# STM32WL5X_CM4 register map
File version: 2.2
CPU: CM4 r0p1, little endian, MPU, no FPU, 4 interrupt priority bits
Registers are 32-bit, read-write, reset 0x0 unless marked. A register's access mark holds for its fields unless they carry their own. Offsets are from the block's base; [hi:lo] are bit positions; {n}, {i} and the like mark numbered series; 'fields as' and 'values as' point back to an identical list.

## GPIOH — General-purpose I/Os
Base 0x48001C00
0x00 MODER reset 0xC0 — GPIO port mode register
  [7:6] MODER3 — Port x configuration bits (y = 0..15)
    0=Input mode (reset state); 1=Output (General purpose output mode); 2=Alternate function mode; 3=Analog mode
0x04 OTYPER — GPIO port output type register
  [3] OT3 — Port x configuration bits (y = 0..15)
    0=PushPull (Output push-pull (reset state)); 1=OpenDrain (Output open-drain)
0x08 OSPEEDR — GPIO port output speed register
  [7:6] OSPEEDR3 — Port x configuration bits (y = 0..15)
    0=LowSpeed; 1=MediumSpeed; 2=HighSpeed; 3=VeryHighSpeed
0x0C PUPDR — GPIO port pull-up/pull-down register
  [7:6] PUPDR3 — Port x configuration bits (y = 0..15)
    0=Floating (No pull-up, pull-down); 1=PullUp; 2=PullDown
0x10 IDR ro — GPIO port input data register
  [3] IDR3 — Port input data (y = 0..15)
    0=Low (Input is logic low); 1=High (Input is logic high)
0x14 ODR — GPIO port output data register
  [3] ODR3 — Port output data (y = 0..15)
    0=Low (Set output to logic low); 1=High (Set output to logic high)
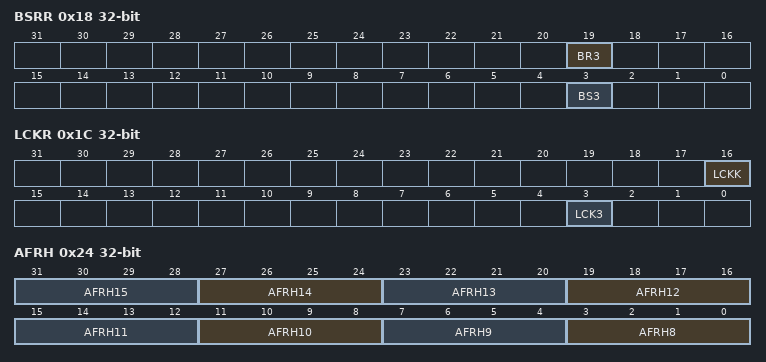
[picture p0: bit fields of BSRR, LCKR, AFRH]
0x18 BSRR wo — GPIO port bit set/reset register
  [19] BR3 — Port x reset bit y (y = 0..15)
    1=Resets the corresponding ODRx bit
  [3] BS3 — Port x set bit y (y= 0..15)
    1=Set (Sets the corresponding ODRx bit)
0x1C LCKR — GPIO port configuration lock register
  [16] LCKK — Port x lock bit y (y= 0..15)
    0=NotActive (Port configuration lock key not active); 1=Active (Port configuration lock key active)
  [3] LCK3 — Port x lock bit y (y= 0..15)
    0=Unlocked (Port configuration not locked); 1=Locked (Port configuration locked)
0x20 AFRL — GPIO alternate function low register
  [15:12] AFRL3 — Alternate function selection for port x bit y (y = 0..7)
    {v}=AF{v} (v=0..15)
0x24 AFRH — GPIO alternate function high register
  [all] fields
    {v}=AF{v} (v=0..15)
  [4n-29:4n-32] AFRH{n} (n=8..15) — Alternate function selection for port x bit y (y = 8..15)
0x28 BRR — GPIO port bit reset register
  [3] BR3 — Port Reset bit
    on write: 0=No action on the corresponding ODx bit; 1=Reset the ODx bit

## HSEM — Hardware semaphore
Base 0x58001400
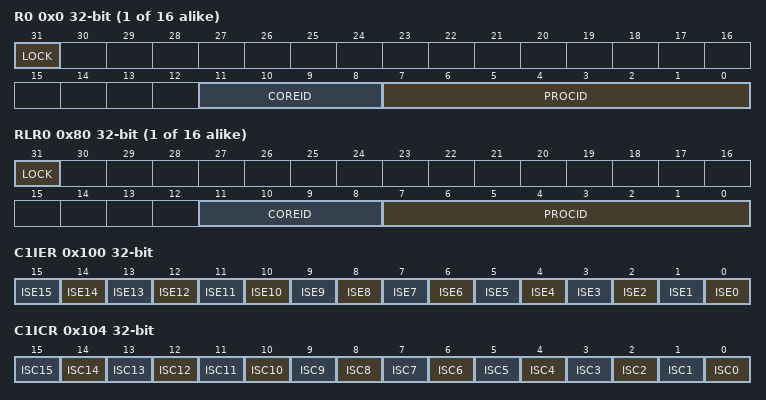
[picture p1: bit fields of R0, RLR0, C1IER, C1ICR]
{0x0+4i} R{i} (i=0..15) — HSEM register HSEM_R{i}
  [31] LOCK — Lock indication
    on read: 0=Free (Semaphore is free); 1=Locked (Semaphore is locked) | on write: 0=Free semaphore; 1=TryLock (Try to lock semaphore)
  [11:8] COREID
  [7:0] PROCID — Semaphore ProcessID
{0x80+4i} RLR{i} (i=0..15) ro — Semaphore {i} read lock register
  [31] LOCK — Lock indication
    0=Free (Semaphore is free); 1=Locked (Semaphore is locked)
  [11:8] COREID
  [7:0] PROCID — Semaphore ProcessID
0x100 C1IER — HSEM Interrupt enable register
  [n] ISE{n} (n=0..15) — Interrupt semaphore {n} enable bit
    0=Disabled (Interrupt generation disabled); 1=Enabled (Interrupt generation enabled)
0x104 C1ICR — HSEM Interrupt clear register
  [n] ISC{n} (n=0..15) — Interrupt semaphore {n} clear bit
    on read: 0=NoEffect (Always reads 0) | on write: 0=NoEffect (Interrupt semaphore x status ISFx and masked status MISFx not affected); 1=Clear (Interrupt semaphore x status ISFx and masked status MISFx cleared)
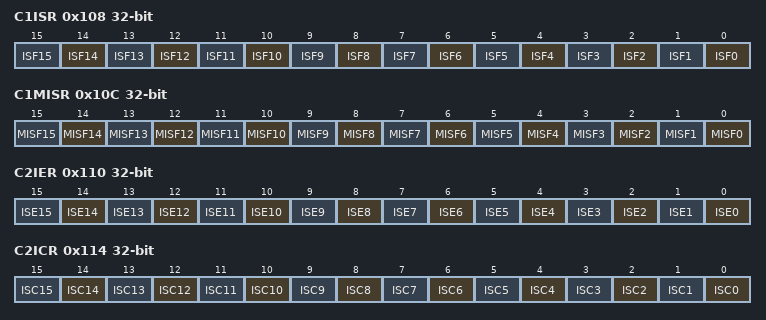
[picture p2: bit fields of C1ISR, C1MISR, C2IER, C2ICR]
0x108 C1ISR ro — HSEM Interrupt status register
  [n] ISF{n} (n=0..15) — Interrupt semaphore {n} status bit before enable (mask)
    0=NotPending (No interrupt pending); 1=Pending (Interrupt pending)
0x10C C1MISR ro — HSEM Masked interrupt status register
  [n] MISF{n} (n=0..15) — Masked interrupt semaphore {n} status bit after enable (mask)
    0=NotPending (No interrupt pending after masking); 1=Pending (Interrupt pending after masking)
0x110 C2IER — HSEM Interrupt enable register
  fields as C1IER
0x114 C2ICR — HSEM Interrupt clear register
  fields as C1ICR
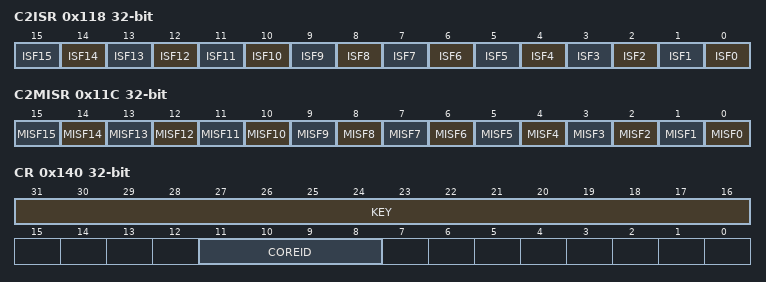
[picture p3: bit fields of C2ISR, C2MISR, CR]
0x118 C2ISR ro — HSEM Interrupt status register
  fields as C1ISR
0x11C C2MISR ro — HSEM Masked interrupt status register
  fields as C1MISR
0x140 CR wo — HSEM Clear register
  [31:16] KEY — Semaphore clear Key
  [11:8] COREID
0x144 KEYR — HSEM Interrupt clear register
  [31:16] KEY — Semaphore Clear Key
